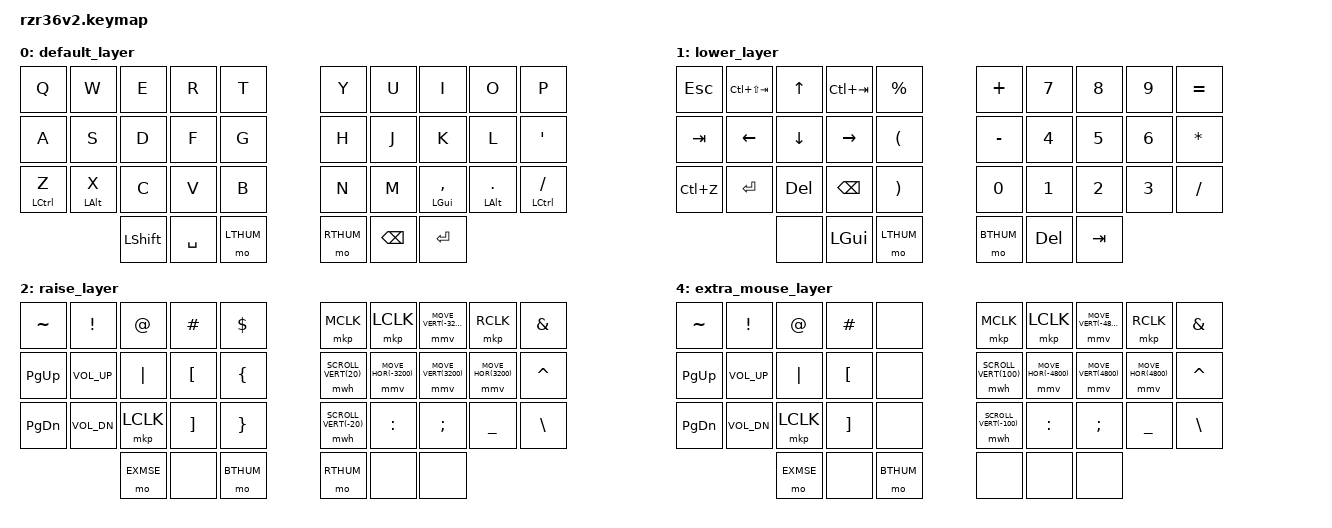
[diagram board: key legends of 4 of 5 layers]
#include <behaviors.dtsi>
#include <dt-bindings/zmk/keys.h>
#include <dt-bindings/zmk/bt.h>
#include <dt-bindings/zmk/outputs.h>
#include <dt-bindings/zmk/mouse.h>

#define DEFAULT 0 
#define LTHUM 1 
#define RTHUM 2
#define BTHUM 3
#define EXMSE 4
#define GAME 5
#define GAME2 6


&mmv {
	time-to-max-speed-ms = <800>;
     };

//&mwh







/{
        keymap {
                compatible = "zmk,keymap";

                default_layer {
// ----------------------------------------------------------------------------------------
// |  Q  |  W  |  E  |  R  |  T  |   |  Y  |  U   |  I  |  O  |  P  |
// |  A  |  S  |  D  |  F  |  G  |   |  H  |  J   |  K  |  L  |  '  |
// |Z/CTL|X/ALT|  C  |  V  |  B  |   |  N  |  M   |,/GUI|./ALT|/_CTL|
//             | Shf | SPC | LTb |   | RTb | BKSP | ENT |
                        bindings = <
   &kp Q      &kp W 	 &kp E     &kp R     &kp T   		&kp Y     &kp U    &kp I    	  &kp O   	   &kp P   
   &kp A      &kp S 	 &kp D     &kp F     &kp G   		&kp H 	  &kp J    &kp K     	  &kp L   	   &kp SQT
   &mt LCTL Z &mt LALT X &kp C     &kp V     &kp B   		&kp N 	  &kp M    &mt LGUI COMMA &mt LALT DOT &mt LCTL FSLH
				         &kp LSHFT &kp SPACE &mo LTHUM      &mo RTHUM &kp BSPC &kp RET
                        >;
                };
                lower_layer {
// -----------------------------------------------------------------------------------------
// | ESC |PTab |  Up |NTab |  %  |   |  +  |  7  |  8  |  9  |  =  |
// | Tab | Left| Down|Right|  (  |   |  -  |  4  |  5  |  6  |  *  |
// | Undo| ENT | DEL |BSPC |  )  |   |  0  |  1  |  2  |  3  |  /  |
//             |     | GUI | LTb |   | BTb | DEL | TAB |
                        bindings = <
   &kp ESC   &kp LC(LS(TAB))  &kp UP    &kp LC(TAB) &kp PRCNT       &kp PLUS   &kp N7  &kp N8 &kp N9  &kp EQUAL 
   &kp TAB   &kp LEFT         &kp DOWN  &kp RIGHT   &kp LPAR        &kp MINUS  &kp N4  &kp N5 &kp N6  &kp STAR 
   &kp LC(Z) &kp RET          &kp DEL   &kp BSPC    &kp RPAR        &kp N0     &kp N1  &kp N2 &kp N3  &kp FSLH 
	  		      &none     &kp LGUI    &mo LTHUM       &mo BTHUM  &kp DEL &kp TAB
                        >;
                };

                raise_layer {
// -----------------------------------------------------------------------------------------
// |  ~  |  !  |  @  |  #  |  $  |     | MMB* |LMB* | MUp*| RMB*|  &  |
// | PgUp|VolUp| '|' | '[' | '{' |     | ScUp*|MLft*| MDn*| MRt*|  ^  |
// | PgDn|VolDn|     | ']' | '}' |     | ScDn*|  :  |  ;  |  _  |  \  |
//             |     |     | BTb |     | RTb  |     |     |
                        bindings = <
   &kp TILDE  &kp EXCL 	   &kp AT    &kp HASH  &kp DLLR       &mkp MCLK             &mkp LCLK            &mmv MOVE_VERT(-3200) &mkp RCLK           &kp AMPS
   &kp PG_UP  &kp C_VOL_UP &kp PIPE  &kp LBKT  &kp LBRC       &mwh SCROLL_VERT(20)  &mmv MOVE_HOR(-3200) &mmv MOVE_VERT(3200)  &mmv MOVE_HOR(3200) &kp CARET
   &kp PG_DN  &kp C_VOL_DN &mkp LCLK &kp RBKT  &kp RBRC       &mwh SCROLL_VERT(-20) &kp COLON            &kp SEMI              &kp UNDER           &kp BSLH
                    	   &mo EXMSE &none     &mo BTHUM      &mo RTHUM             &none                &none
                        >;
                };
				
				combo_layer {
// -----------------------------------------------------------------------------------------
// |  `  |  F1 |  F2 |  F3 |  F4 |        |     |     |     |     |TxtSt|
// | INS |  F5 |  F6 |  F7 |  F8 |        |     |     |     |     |ScnSt|
// | NumL|  F9 | F10 | F11 | F12 |        |     |     |     |     |     |
//             |GAME*|     |  |        |     |     |     |
                        bindings = <
   &kp GRAVE &kp F1   &kp F2  &kp F3  &kp F4           &none             &bt BT_SEL 0      &none         &bt      &kp LG(LS(T))
   &none     &kp F5   &kp F6  &kp F7  &kp F8           &none             &none            &none         &kp NUHS &kp LG(LS(S))
   &none     &kp F9   &kp F10 &kp F11 &kp F12          &kp LG(LC(LA(NUMBER_1))) &kp LG(LC(LA(NUMBER_2))) &none    &trans        &kp LG(LS(D))
   	  	&bootloader &none   &trans         &trans            &none             &bt BT_CLR
                        >;

		};
			
                extra_mouse_layer {
// -----------------------------------------------------------------------------------------
// |  ~  |  !  |  @  |  #  |  $  |     | MMB* |LMB* | MUp*| RMB*|  &  |
// | PgUp|VolUp| '|' | '[' | '{' |     | ScUp*|MLft*| MDn*| MRt*|  ^  |
// | PgDn|VolDn|     | ']' | '}' |     | ScDn*|  :  |  ;  |  _  |  \  |
//             |     |     | BTb |     | RTb  |     |     |
                        bindings = <
   &kp TILDE  &kp EXCL 	   &kp AT    &kp HASH  &none       &mkp MCLK             &mkp LCLK            &mmv MOVE_VERT(-4800) &mkp RCLK           &kp AMPS
   &kp PG_UP  &kp C_VOL_UP &kp PIPE  &kp LBKT  &none       &mwh SCROLL_VERT(100)  &mmv MOVE_HOR(-4800) &mmv MOVE_VERT(4800)  &mmv MOVE_HOR(4800) &kp CARET
   &kp PG_DN  &kp C_VOL_DN &mkp LCLK &kp RBKT  &none       &mwh SCROLL_VERT(-100) &kp COLON            &kp SEMI              &kp UNDER           &kp BSLH
                    	   &mo EXMSE &none     &mo BTHUM   &none                 &none                &none
                        >;
                };
							
				
				
				
        };
};
